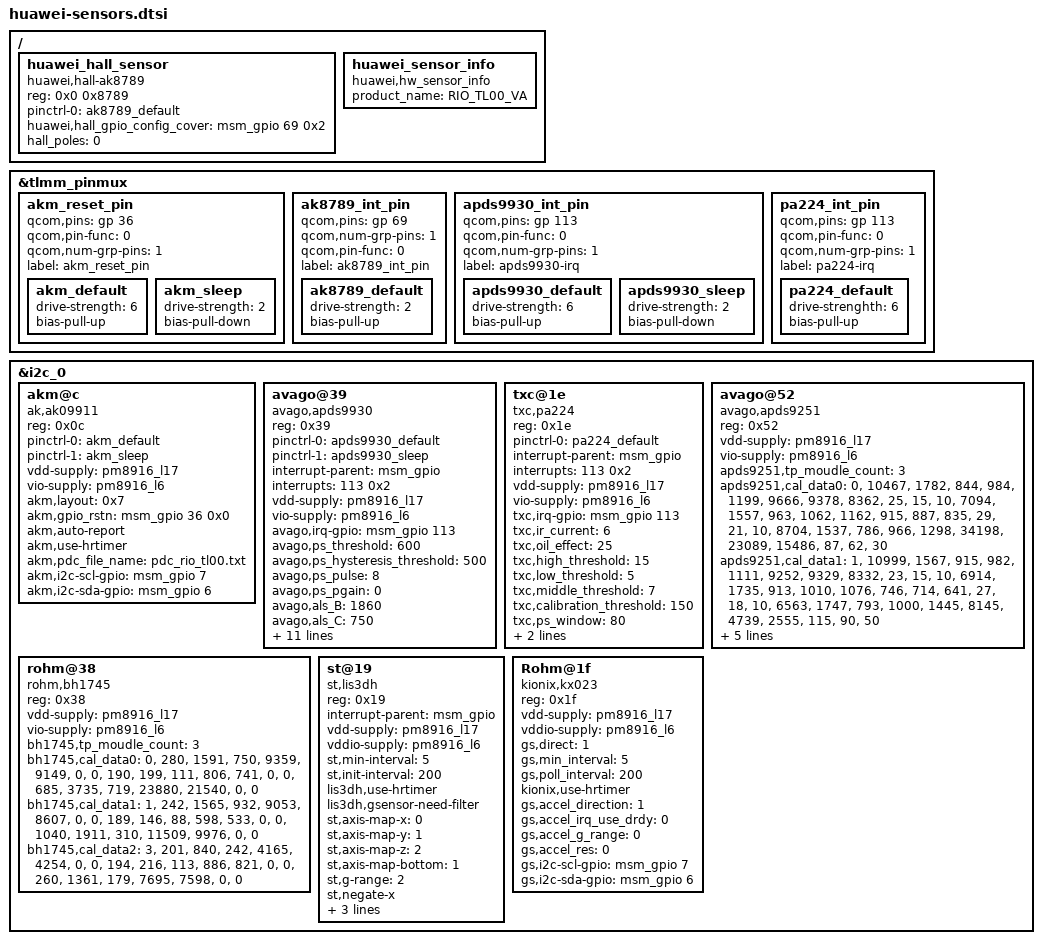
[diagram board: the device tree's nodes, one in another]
/*use fromdos convert file format to linux*/
/* Copyright (c) 2013 The Linux Foundation. All rights reserved.
 *
 * This program is free software; you can redistribute it and/or modify
 * it under the terms of the GNU General Public License version 2 and
 * only version 2 as published by the Free Software Foundation.
 *
 * This program is distributed in the hope that it will be useful,
 * but WITHOUT ANY WARRANTY; without even the implied warranty of
 * MERCHANTABILITY or FITNESS FOR A PARTICULAR PURPOSE.  See the
 * GNU General Public License for more details.
 */
&tlmm_pinmux {
	akm_reset_pin {
		qcom,pins = <&gp 36>;
		qcom,pin-func = <0>;
		qcom,num-grp-pins = <1>;
		label = "akm_reset_pin";
		akm_default: akm_default {
			drive-strength = <6>;
			bias-pull-up;
		};
		akm_sleep: akm_sleep {
			drive-strength = <2>;
			bias-pull-down;
		};
	};
//delete lines
	ak8789_int_pin {
		qcom,pins = <&gp 69>;
		qcom,num-grp-pins = <1>;
		qcom,pin-func = <0>;
		label = "ak8789_int_pin";
		ak8789_default: ak8789_default {
			  drive-strength = <2>;
			  bias-pull-up;
		};
	};
	apds9930_int_pin {
		qcom,pins = <&gp 113>;
		qcom,pin-func = <0>;
		qcom,num-grp-pins = <1>;
		label = "apds9930-irq";
		apds9930_default: apds9930_default {
			drive-strength = <6>;
			bias-pull-up;
		};
		apds9930_sleep: apds9930_sleep {
			drive-strength = <2>;
			bias-pull-down;
		};
	};
	pa224_int_pin {
		qcom,pins = <&gp 113>;
		qcom,pin-func = <0>;
		qcom,num-grp-pins = <1>;
		label = "pa224-irq";
		pa224_default: pa224_default {
			drive-strenghth = <6>;
			bias-pull-up;
		};
	};
};

&i2c_0 { /* BLSP1 QUP2 */
	akm@c {
		compatible = "ak,ak09911";
		reg = <0x0c>;
		pinctrl-names = "default","sleep";
		pinctrl-0 = <&akm_default>;
		pinctrl-1 = <&akm_sleep>;
		vdd-supply = <&pm8916_l17>;
		vio-supply = <&pm8916_l6>;
		akm,layout = <0x7>;
		akm,gpio_rstn = <&msm_gpio 36 0x0>;
		akm,auto-report;
		akm,use-hrtimer;
		akm,pdc_file_name = "pdc_rio_tl00.txt";
		akm,i2c-scl-gpio = <&msm_gpio 7 0x0>;
		akm,i2c-sda-gpio = <&msm_gpio 6 0x0>;
	};

	avago@39 {
		compatible = "avago,apds9930";
		reg = <0x39>;
		pinctrl-names = "default","sleep";
		pinctrl-0 = <&apds9930_default>;
		pinctrl-1 = <&apds9930_sleep>;
		interrupt-parent = <&msm_gpio>;
		interrupts = <113 0x2>;
		vdd-supply = <&pm8916_l17>;
		vio-supply = <&pm8916_l6>;
		avago,irq-gpio = <&msm_gpio 113 0x2>;
		avago,ps_threshold = <600>;
		avago,ps_hysteresis_threshold = <500>;
		avago,ps_pulse = <8>;
		avago,ps_pgain = <0>;
		avago,als_B = <1860>;
		avago,als_C = <750>;
		avago,als_D = <1290>;
		avago,ga_value = <48>;
	        avago,ga_a_value = <112>;
		avago,ga_c_value = <450>;
		avago,ga_d_value = <162>;
		avago,window = <110>;
		avago,wave = <84>;
		avago,ga_e_value = <220>;
		avago,ga_f_value = <43>;
		avago,i2c-scl-gpio = <&msm_gpio 7 0x0>;
		avago,i2c-sda-gpio = <&msm_gpio 6 0x0>;
	};
	txc@1e {
		compatible = "txc,pa224";
		reg = <0x1e>;
		pinctrl-names = "default";
		pinctrl-0 = <&pa224_default>;
		interrupt-parent = <&msm_gpio>;
		interrupts = <113 0x2>;
		vdd-supply = <&pm8916_l17>;
		vio-supply = <&pm8916_l6>;
		txc,irq-gpio = <&msm_gpio 113 0x2>;
		/*IR CURRENT 10MA*/
		txc,ir_current = <6>;
		txc,oil_effect = <25>;
		txc,high_threshold = <15>;
		txc,low_threshold = <5>;
		txc,middle_threshold = <7>;
		txc,calibration_threshold = <150>;
		txc,ps_window = <80>;
		txc,ps_wave = <40>;
		txc,ps_defalt_crosstalk = <50>;

	};
	avago@52 {
		compatible = "avago,apds9251";
		reg = <0x52>;
		vdd-supply = <&pm8916_l17>;
		vio-supply = <&pm8916_l6>;
		apds9251,tp_moudle_count = <3>;
		/*[module_id] [CCT_M] [CCT_N] [H] [A] [D] [LUX_P] [LUX_Q] [LUX_R] [cofficient0] [cofficient1] [cofficient2]*/
		apds9251,cal_data0 = "0","10467","1782","844","984","1199","9666","9378","8362","25","15","10",
		/*[CCT_M] [CCT_N] [H] [A] [D] [LUX_P] [LUX_Q] [LUX_R] [cofficient0] [cofficient1] [cofficient2]*/
		"7094","1557","963","1062","1162","915","887","835","29","21","10",
		/*[CCT_M] [CCT_N] [H] [A] [D] [LUX_P] [LUX_Q] [LUX_R] [cofficient0] [cofficient1] [cofficient2]*/
		"8704","1537","786","966","1298","34198","23089","15486","87","62","30";
		/*[module_id] [CCT_M] [CCT_N] [H] [A] [D] [LUX_P] [LUX_Q] [LUX_R] [cofficient0] [cofficient1] [cofficient2]*/
		apds9251,cal_data1 = "1","10999","1567","915","982","1111","9252","9329","8332","23","15","10",
		/*[CCT_M] [CCT_N] [H] [A] [D] [LUX_P] [LUX_Q] [LUX_R] [cofficient0] [cofficient1] [cofficient2]*/
		"6914","1735","913","1010","1076","746","714","641","27","18","10",
		/*[CCT_M] [CCT_N] [H] [A] [D] [LUX_P] [LUX_Q] [LUX_R] [cofficient0] [cofficient1] [cofficient2]*/
		"6563","1747","793","1000","1445","8145","4739","2555","115","90","50";
		/*[module_id] [CCT_M] [CCT_N] [H] [A] [D] [LUX_P] [LUX_Q] [LUX_R] [cofficient0] [cofficient1] [cofficient2]*/
		apds9251,cal_data2 = "3","8796","1738","882","993","1092","5047","4989","4511","21","14","5",
		/*[CCT_M] [CCT_N] [H] [A] [D] [LUX_P] [LUX_Q] [LUX_R] [cofficient0] [cofficient1] [cofficient2]*/
		"6491","1636","946","1054","1159","1043","1004","940","30","19","10",
		/*[CCT_M] [CCT_N] [H] [A] [D] [LUX_P] [LUX_Q] [LUX_R] [cofficient0] [cofficient1] [cofficient2]*/
		"11215","1620","798","1100","1100","7853","9975","8486","47","25","10";
	};
	rohm@38 {
		compatible = "rohm,bh1745";
		reg = <0x38>;
		vdd-supply = <&pm8916_l17>;
		vio-supply = <&pm8916_l6>;
		bh1745,tp_moudle_count = <3>;
		/*[module_id] [golden judge] r[0] r[1] g[0] g[1] b[0] b[1]*/
		bh1745,cal_data0 = "0","280","1591","750","9359","9149","0","0",
		/*[white judge] r[0] r[1] g[0] g[1] b[0] b[1]*/
		"190","199","111","806","741","0","0",
		/*[black judge] r[0] r[1] g[0] g[1] b[0] b[1]*/
		"685","3735","719","23880","21540","0","0";
		/*[module_id] [golden judge] r[0] r[1] g[0] g[1] b[0] b[1]*/
		bh1745,cal_data1 = "1","242","1565","932","9053","8607","0","0",
		/*[white judge] r[0] r[1] g[0] g[1] b[0] b[1]*/
		"189","146","88","598","533","0","0",
		/*[black judge] r[0] r[1] g[0] g[1] b[0] b[1]*/
		"1040","1911","310","11509","9976","0","0";
		/*[module_id] [golden judge] r[0] r[1] g[0] g[1] b[0] b[1]*/
		bh1745,cal_data2 = "3","201","840","242","4165","4254","0","0",
		/*[white judge] r[0] r[1] g[0] g[1] b[0] b[1]*/
		"194","216","113","886","821","0","0",
		/*[black judge] r[0] r[1] g[0] g[1] b[0] b[1]*/
		"260","1361","179","7695","7598","0","0";
	};

	st@19 {
		compatible = "st,lis3dh";
		reg = <0x19>;
//delete lines
		interrupt-parent = <&msm_gpio>;
		vdd-supply = <&pm8916_l17>;
		vddio-supply = <&pm8916_l6>;
		st,min-interval = <5>;
		st,init-interval = <200>;
		lis3dh,use-hrtimer;
		lis3dh,gsensor-need-filter;
		st,axis-map-x = <0>;
		st,axis-map-y = <1>;
		st,axis-map-z = <2>;
		/*1 is bottom and others means top*/
		st,axis-map-bottom=<1>;
		st,g-range = <2>;
//delete lines
		st,negate-x;
		st,negate-y;
		st,i2c-scl-gpio = <&msm_gpio 7 0x0>;
		st,i2c-sda-gpio = <&msm_gpio 6 0x0>;
	};
	Rohm@1f {
		compatible = "kionix,kx023";
		reg = <0x1f>;
//delete lines
		vdd-supply = <&pm8916_l17>;
		vddio-supply = <&pm8916_l6>;
//delete lines
		/*1 is bottom and others means top*/
		gs,direct = <1>;
		gs,min_interval = <5>;
		gs,poll_interval = <200>;
		kionix,use-hrtimer;
		gs,accel_direction = <1>;
		gs,accel_irq_use_drdy = <0>;
		gs,accel_g_range = <0>;
		gs,accel_res = <0>;
		gs,i2c-scl-gpio = <&msm_gpio 7 0x0>;
		gs,i2c-sda-gpio = <&msm_gpio 6 0x0>;
	};
	//drop the sar sensor
};
/{
	huawei_hall_sensor{
		compatible = "huawei,hall-ak8789";
		reg = <0x0 0x8789>;
		pinctrl-names = "default";
		pinctrl-0 = <&ak8789_default>;
		huawei,hall_gpio_config_cover = <&msm_gpio 69 0x2>;
		hall_poles = <0>;
		status = "ok";
	};
};
/{
	huawei_sensor_info {
		compatible = "huawei,hw_sensor_info";
		product_name = "RIO_TL00_VA";
	};
};
